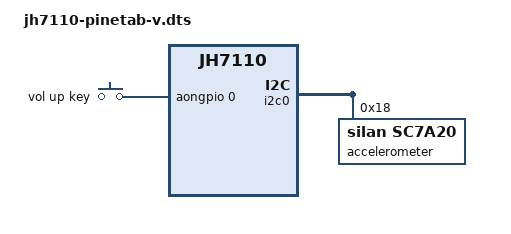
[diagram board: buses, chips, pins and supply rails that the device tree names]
// SPDX-License-Identifier: GPL-2.0 OR MIT
/*
 * Copyright (C) 2022 StarFive Technology Co., Ltd.
 * Copyright (C) 2022 Hal Feng <hal.feng@starfivetech.com>
 */

/dts-v1/;

#include "jh7110-pinetab-v.dtsi"

&gpio_keys {
	vol-up-key {
		label = "vol up key";
		debounce-interval = <10>;
		linux,input-type = <EV_KEY>;
		linux,code = <KEY_VOLUMEUP>;
		gpios = <&aongpio 0 GPIO_ACTIVE_HIGH>;
	};
};

&i2c0 {
	accelerometer@18 {
		compatible = "silan,sc7a20";
		reg = <0x18>;
		mount-matrix =	 "-1",  "0",  "0",
				  "0",  "0", "-1",
				  "0",  "1",  "0";
	};
};

&panel {
	reset-gpio = <&sysgpio 51 GPIO_ACTIVE_LOW>;
};
